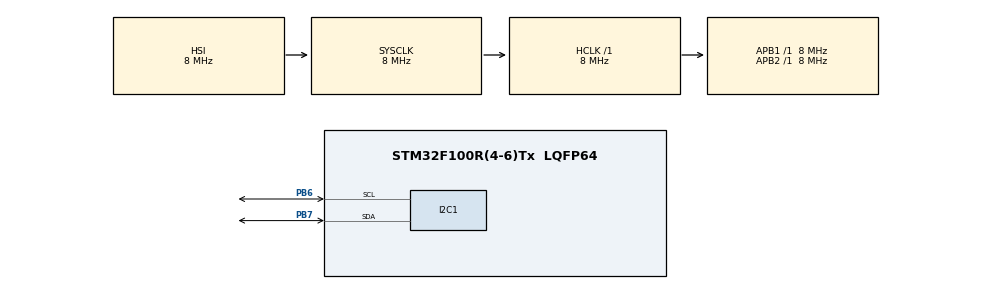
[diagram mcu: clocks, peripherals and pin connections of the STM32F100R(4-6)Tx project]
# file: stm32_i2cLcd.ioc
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I2C1.I2C_Mode=I2C_Fast
Mcu.Family=STM32F1
Mcu.Name=STM32F100R(4-6)Tx
Mcu.Package=LQFP64
NVIC.PriorityGroup=NVIC_PRIORITYGROUP_4
PA13.Mode=Serial_Wire
PA13.Signal=SYS_JTMS-SWDIO
PA14.Mode=Serial_Wire
PA14.Signal=SYS_JTCK-SWCLK
PB6.Mode=I2C
PB6.Signal=I2C1_SCL
PB7.Mode=I2C
PB7.Signal=I2C1_SDA
ProjectManager.HeapSize=0x200
ProjectManager.StackSize=0x400
ProjectManager.TargetToolchain=STM32CubeIDE
RCC.AHBFreq_Value=8000000
RCC.APB1Freq_Value=8000000
RCC.APB1TimFreq_Value=8000000
RCC.APB2Freq_Value=8000000
RCC.APB2TimFreq_Value=8000000
RCC.HCLKFreq_Value=8000000
RCC.PLLMUL=RCC_PLL_MUL4
RCC.SYSCLKFreq_VALUE=8000000
board=custom

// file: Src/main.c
/* USER CODE BEGIN Header */
/**
  ******************************************************************************
  * @file           : main.c
  * @brief          : Main program body
  ******************************************************************************
  * @attention
  *
  * <h2><center>&copy; Copyright (c) 2019 STMicroelectronics.
  * All rights reserved.</center></h2>
  *
  * This software component is licensed by ST under BSD 3-Clause license,
  * the "License"; You may not use this file except in compliance with the
  * License. You may obtain a copy of the License at:
  *                        opensource.org/licenses/BSD-3-Clause
  *
  ******************************************************************************
  */
/* USER CODE END Header */

#include "main.h"

I2C_HandleTypeDef hi2c1;
i2cLcd_HandleTypeDef h_lcd;

void SystemClock_Config(void);
static void MX_GPIO_Init(void);
static void MX_I2C1_Init(void);

/* USER CODE BEGIN 0 */

void print_long_text(i2cLcd_HandleTypeDef *h_lcd, char * text){
	char txt[32] = "Some very very long text\0";
	int i;
	i=0;
	if(text == NULL) {
		text = txt;
	}

	while(text[i]){
		i2cLcd_SendChar(h_lcd, text[i]);
		i++;
	}
}

uint8_t cchar1[8] ={ 0b00001000,
					0b01110100,
					0b01000010,
					0b01000001,
					0b01000010,
					0b01000100,
					0b01001000,
					0b00000000
};

uint8_t cchar2[8] ={0b01000,
					0b00000,
					0b11111,
					0b01010,
					0b00100,
					0b01010,
					0b10001,
					0b00000
};

uint8_t ch_smiley[8] ={	0b00000,
						0b00000,
						0b01010,
						0b00000,
						0b10001,
						0b01110,
						0b00000,
						0b00000
};
uint8_t ch_sadley[8] ={	0b00000,
						0b00000,
						0b01010,
						0b00000,
						0b01110,
						0b10001,
						0b00000,
						0b00000
};
uint8_t ch_hearty[8] ={	0b00000,
						0b00000,
						0b11011,
						0b11111,
						0b01110,
						0b00100,
						0b00000,
						0b00000
};

uint8_t ch_skully[8] ={	0b00000,
						0b01110,
						0b10101,
						0b11111,
						0b11111,
						0b01010,
						0b01010,
						0b00000
};

void test_some_features(i2cLcd_HandleTypeDef *h_lcd){
	char text[32] = "Some very very long text\0";
	uint8_t addr;

	i2cLcd_ClearDisplay(h_lcd);

	i2cLcd_EntryIncrEn(h_lcd, 0);
	i2cLcd_EntryShiftEn(h_lcd, 0);
	print_long_text(h_lcd, "some long very text now\0");

	i2cLcd_ClearDisplay(h_lcd);

	i2cLcd_EntryIncrEn(h_lcd, 1);
	i2cLcd_EntryShiftEn(h_lcd, 0);
	print_long_text(h_lcd, "some long very text now\0");

	i2cLcd_ClearDisplay(h_lcd);

	i2cLcd_EntryIncrEn(h_lcd, 0);
	i2cLcd_EntryShiftEn(h_lcd, 1);
	print_long_text(h_lcd, "some long very text now\0");

	i2cLcd_ClearDisplay(h_lcd);

	i2cLcd_EntryIncrEn(h_lcd, 1);
	i2cLcd_EntryShiftEn(h_lcd, 1);
	print_long_text(h_lcd, "some long very text now\0");

	i2cLcd_ClearDisplay(h_lcd);

	i2cLcd_SetCursorPosition(h_lcd, 16);
	i2cLcd_EntryIncrEn(h_lcd, 0);
	i2cLcd_EntryShiftEn(h_lcd, 1);
	print_long_text(h_lcd, "some long very text now\0");

	i2cLcd_ClearDisplay(h_lcd);

	i2cLcd_SetCursorPosition(h_lcd, 5);
	i2cLcd_EntryIncrEn(h_lcd, 1);
	i2cLcd_EntryShiftEn(h_lcd, 1);
	print_long_text(h_lcd, "some long very text now\0");
	print_long_text(h_lcd, "123456789abcdefghijklmop\0");

	//i2cLcd_SetCursorPosition(h_lcd, 4);

	i2cLcd_Shift(h_lcd,0,0);
	i2cLcd_Shift(h_lcd,0,1);
	i2cLcd_Shift(h_lcd,1,0);

	i2cLcd_Shift(h_lcd,1,1);

	i2cLcd_ClearDisplay(h_lcd);

	i2cLcd_Init(h_lcd);

	// playing around with custom chars
	i2cLcd_SendChar(h_lcd, 'a');
	i2cLcd_SendChar(h_lcd, 0);
	i2cLcd_SendChar(h_lcd, 1);

	i2cLcd_WriteCustomChar(h_lcd, 1, cchar2);

	i2cLcd_SendChar(h_lcd, 'a');

	i2cLcd_SendChar(h_lcd, 0);

	i2cLcd_WriteCustomChar(h_lcd, 0, cchar1);

	i2cLcd_SendChar(h_lcd, 1);

	i2cLcd_ClearDisplay(h_lcd);
	print_long_text(h_lcd, "Custom character\0");

	i2cLcd_SetCursorPosition(h_lcd, 40);
	i2cLcd_SendChar(h_lcd, 'z');
	i2cLcd_WriteCustomChar(h_lcd, 0, ch_smiley);
	i2cLcd_WriteCustomChar(h_lcd, 1, ch_sadley);
	i2cLcd_WriteCustomChar(h_lcd, 2, ch_hearty);
	i2cLcd_WriteCustomChar(h_lcd, 3, ch_skully);
	i2cLcd_SendChar(h_lcd, 0);
	i2cLcd_SendChar(h_lcd, 1);
	i2cLcd_SendChar(h_lcd, 2);
	i2cLcd_SendChar(h_lcd, 3);

	addr = 0;
	i2cLcd_GetCursorPosition(h_lcd, &addr);

}

/* USER CODE END 0 */

int main(void)
{
  /* USER CODE BEGIN 1 */
	uint8_t i2c_lcd_addr = (0x20<<1);
	char strData[32];
	uint8_t data;
	uint8_t i;
	uint8_t j;

  /* USER CODE END 1 */

  /* MCU Configuration--------------------------------------------------------*/

  /* Reset of all peripherals, Initializes the Flash interface and the Systick. */
  HAL_Init();

  /* Configure the system clock */
  SystemClock_Config();

  /* Initialize all configured peripherals */
  MX_GPIO_Init();
  MX_I2C1_Init();

  /* USER CODE BEGIN 2 */

  HAL_Delay(100);

  i2cLcd_CreateHandle(&h_lcd, &hi2c1, i2c_lcd_addr);

  i2cLcd_Init(&h_lcd);

  i2cLcd_ClearDisplay(&h_lcd);

  i=0;
  j=0;

  /* USER CODE END 2 */

  /* Infinite loop */
  /* USER CODE BEGIN WHILE */

  HAL_Delay(500);

  test_some_features(&h_lcd);

  i2cLcd_Init(&h_lcd);

  while (1){
	  i2cLcd_ClearDisplay(&h_lcd);
	  HAL_Delay(20);
	  sprintf(strData,"STM32F100");
	  while(strData[i]) {
		  i2cLcd_SendChar(&h_lcd, strData[i]);
		  //HAL_Delay(100);
		  i++;
	  }

	  // test reading address cursor
	  i2cLcd_ReadByte(&h_lcd, &data);

	  i2cLcd_SetCursorPosition(&h_lcd, 0x40);
	  i=0;
	  sprintf(strData,"I2C LCD Library");
	  while(strData[i]) {
		  i2cLcd_SendChar(&h_lcd, strData[i]);
		  //HAL_Delay(100);
		  i++;
	  }

	  i2cLcd_SendChar(&h_lcd, 0x7E);
	  HAL_Delay(2000);

	  i=0;
	  j++;
    /* USER CODE END WHILE */
  }
}

void SystemClock_Config(void)
{
  RCC_OscInitTypeDef RCC_OscInitStruct = {0};
  RCC_ClkInitTypeDef RCC_ClkInitStruct = {0};

  /** Initializes the CPU, AHB and APB busses clocks
  */
  RCC_OscInitStruct.OscillatorType = RCC_OSCILLATORTYPE_HSI;
  RCC_OscInitStruct.HSIState = RCC_HSI_ON;
  RCC_OscInitStruct.HSICalibrationValue = RCC_HSICALIBRATION_DEFAULT;
  RCC_OscInitStruct.PLL.PLLState = RCC_PLL_NONE;
  if (HAL_RCC_OscConfig(&RCC_OscInitStruct) != HAL_OK)
  {
    Error_Handler();
  }
  /** Initializes the CPU, AHB and APB busses clocks
  */
  RCC_ClkInitStruct.ClockType = RCC_CLOCKTYPE_HCLK|RCC_CLOCKTYPE_SYSCLK
                              |RCC_CLOCKTYPE_PCLK1|RCC_CLOCKTYPE_PCLK2;
  RCC_ClkInitStruct.SYSCLKSource = RCC_SYSCLKSOURCE_HSI;
  RCC_ClkInitStruct.AHBCLKDivider = RCC_SYSCLK_DIV1;
  RCC_ClkInitStruct.APB1CLKDivider = RCC_HCLK_DIV1;
  RCC_ClkInitStruct.APB2CLKDivider = RCC_HCLK_DIV1;

  if (HAL_RCC_ClockConfig(&RCC_ClkInitStruct, FLASH_LATENCY_0) != HAL_OK)
  {
    Error_Handler();
  }
}

static void MX_I2C1_Init(void)
{

  hi2c1.Instance = I2C1;
  hi2c1.Init.ClockSpeed = 400000;
  hi2c1.Init.DutyCycle = I2C_DUTYCYCLE_2;
  hi2c1.Init.OwnAddress1 = 0;
  hi2c1.Init.AddressingMode = I2C_ADDRESSINGMODE_7BIT;
  hi2c1.Init.DualAddressMode = I2C_DUALADDRESS_DISABLE;
  hi2c1.Init.OwnAddress2 = 0;
  hi2c1.Init.GeneralCallMode = I2C_GENERALCALL_DISABLE;
  hi2c1.Init.NoStretchMode = I2C_NOSTRETCH_DISABLE;
  if (HAL_I2C_Init(&hi2c1) != HAL_OK)
  {
    Error_Handler();
  }

}

static void MX_GPIO_Init(void)
{

  /* GPIO Ports Clock Enable */
  __HAL_RCC_GPIOA_CLK_ENABLE();
  __HAL_RCC_GPIOB_CLK_ENABLE();

}

void Error_Handler(void)
{
}

/************************ (C) COPYRIGHT STMicroelectronics *****END OF FILE****/
